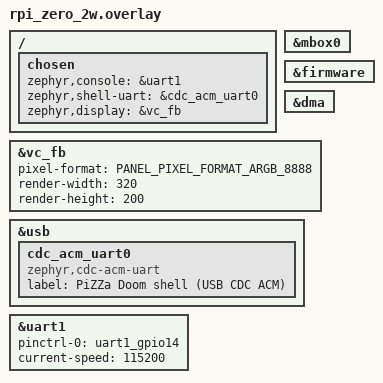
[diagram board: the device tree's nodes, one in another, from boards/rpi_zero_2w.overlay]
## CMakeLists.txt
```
# SPDX-License-Identifier: Apache-2.0
#
# PiZZa -- sdl2-doom via the shared minimal SDL2 shim (apps/lib/sdl2shim).
#
# Links the AlexOberhofer/sdl2-doom game sources (pure C, Chocolate-Doom
# lineage, UNTOUCHED at ~/github/sdl2-doom) against the shim. The one
# concession to "untouched" is a build-time rewrite of i_video.c's
# SDL_RESX/SDL_RESY from *3 to native 320x200: the fork bakes a 3x
# software upscale we do not want (the VC4 HVS scales instead). The
# checkout is not modified -- only a generated copy in the build tree.
#
# sdl2-doom is GPL-2.0; this binary is GPL-2.0 by virtue of linking it.
# The shim + port glue are Apache-2.0, same model as the SDLPoP port.

cmake_minimum_required(VERSION 3.20.0)

find_package(Zephyr REQUIRED HINTS $ENV{ZEPHYR_BASE})
project(pizza-doom C ASM)

# sample_usbd helper for the USB CDC ACM shell (rpi_zero_2w), same as
# PizzaShell / wipeout / SDLPoP.
if(CONFIG_USB_DEVICE_STACK_NEXT)
  include(${ZEPHYR_BASE}/samples/subsys/usb/common/common.cmake)
endif()

# ── Doom game tree (untouched) ──────────────────────────────────────
if(NOT DEFINED DOOM_SRC_DIR)
  set(DOOM_SRC_DIR "$ENV{HOME}/github/sdl2-doom/src")
endif()
if(NOT EXISTS "${DOOM_SRC_DIR}/d_main.c")
  message(FATAL_ERROR
    "sdl2-doom sources not found at ${DOOM_SRC_DIR}. Clone "
    "https://github.com/AlexOberhofer/sdl2-doom and keep it at "
    "~/github/sdl2-doom or pass -DDOOM_SRC_DIR=<path>.")
endif()

# The fork's own build list (its CMakeLists), minus i_cdmus.c (SDL 1.2
# CD API, absent in SDL2; grep confirms nothing else references
# I_CDMus*) and minus i_video.c, which is fed in rewritten below.
set(DOOM_GAME_SRC
  ${DOOM_SRC_DIR}/i_main.c ${DOOM_SRC_DIR}/dummy.c ${DOOM_SRC_DIR}/am_map.c
  ${DOOM_SRC_DIR}/doomdef.c ${DOOM_SRC_DIR}/doomstat.c ${DOOM_SRC_DIR}/dstrings.c
  ${DOOM_SRC_DIR}/d_event.c ${DOOM_SRC_DIR}/d_items.c ${DOOM_SRC_DIR}/d_iwad.c
  ${DOOM_SRC_DIR}/d_loop.c ${DOOM_SRC_DIR}/d_main.c ${DOOM_SRC_DIR}/d_mode.c
  ${DOOM_SRC_DIR}/d_net.c ${DOOM_SRC_DIR}/f_finale.c ${DOOM_SRC_DIR}/f_wipe.c
  ${DOOM_SRC_DIR}/g_game.c ${DOOM_SRC_DIR}/hu_lib.c ${DOOM_SRC_DIR}/hu_stuff.c
  ${DOOM_SRC_DIR}/info.c ${DOOM_SRC_DIR}/i_endoom.c ${DOOM_SRC_DIR}/i_joystick.c
  ${DOOM_SRC_DIR}/i_scale.c ${DOOM_SRC_DIR}/i_sound.c ${DOOM_SRC_DIR}/i_sdlmusic.c
  ${DOOM_SRC_DIR}/i_sdlsound.c ${DOOM_SRC_DIR}/i_system.c ${DOOM_SRC_DIR}/i_timer.c
  ${DOOM_SRC_DIR}/i_input.c ${DOOM_SRC_DIR}/mus2mid.c ${DOOM_SRC_DIR}/memio.c
  ${DOOM_SRC_DIR}/m_argv.c ${DOOM_SRC_DIR}/m_bbox.c ${DOOM_SRC_DIR}/m_cheat.c
  ${DOOM_SRC_DIR}/m_config.c ${DOOM_SRC_DIR}/m_controls.c ${DOOM_SRC_DIR}/m_fixed.c
  ${DOOM_SRC_DIR}/m_menu.c ${DOOM_SRC_DIR}/m_misc.c ${DOOM_SRC_DIR}/m_random.c
  ${DOOM_SRC_DIR}/p_ceilng.c ${DOOM_SRC_DIR}/p_doors.c ${DOOM_SRC_DIR}/p_enemy.c
  ${DOOM_SRC_DIR}/p_floor.c ${DOOM_SRC_DIR}/p_inter.c ${DOOM_SRC_DIR}/p_lights.c
  ${DOOM_SRC_DIR}/p_map.c ${DOOM_SRC_DIR}/p_maputl.c ${DOOM_SRC_DIR}/p_mobj.c
  ${DOOM_SRC_DIR}/p_plats.c ${DOOM_SRC_DIR}/p_pspr.c ${DOOM_SRC_DIR}/p_saveg.c
  ${DOOM_SRC_DIR}/p_setup.c ${DOOM_SRC_DIR}/p_sight.c ${DOOM_SRC_DIR}/p_spec.c
  ${DOOM_SRC_DIR}/p_switch.c ${DOOM_SRC_DIR}/p_telept.c ${DOOM_SRC_DIR}/p_tick.c
  ${DOOM_SRC_DIR}/p_user.c ${DOOM_SRC_DIR}/r_bsp.c ${DOOM_SRC_DIR}/r_data.c
  ${DOOM_SRC_DIR}/r_draw.c ${DOOM_SRC_DIR}/r_main.c ${DOOM_SRC_DIR}/r_plane.c
  ${DOOM_SRC_DIR}/r_segs.c ${DOOM_SRC_DIR}/r_sky.c ${DOOM_SRC_DIR}/r_things.c
  ${DOOM_SRC_DIR}/sha1.c ${DOOM_SRC_DIR}/sounds.c ${DOOM_SRC_DIR}/statdump.c
  ${DOOM_SRC_DIR}/st_lib.c ${DOOM_SRC_DIR}/st_stuff.c ${DOOM_SRC_DIR}/s_sound.c
  ${DOOM_SRC_DIR}/tables.c ${DOOM_SRC_DIR}/v_video.c ${DOOM_SRC_DIR}/wi_stuff.c
  ${DOOM_SRC_DIR}/w_checksum.c ${DOOM_SRC_DIR}/w_file.c ${DOOM_SRC_DIR}/w_main.c
  ${DOOM_SRC_DIR}/w_wad.c ${DOOM_SRC_DIR}/z_zone.c ${DOOM_SRC_DIR}/w_file_stdc.c
)

# i_video.c rewritten to native 320x200 (SDL_RESX/Y *3 -> plain). Keeps
# the checkout pristine; the whole delta is this two-line sed.
set(DOOM_IVIDEO_GEN ${CMAKE_BINARY_DIR}/gen/i_video_320.c)
add_custom_command(
  OUTPUT ${DOOM_IVIDEO_GEN}
  COMMAND ${CMAKE_COMMAND} -E make_directory ${CMAKE_BINARY_DIR}/gen
  COMMAND ${CMAKE_COMMAND} -E copy ${DOOM_SRC_DIR}/i_video.c ${DOOM_IVIDEO_GEN}
  COMMAND sed -i.bak
          -e "s|#define SDL_RESX 320 \\* 3|#define SDL_RESX 320|"
          -e "s|#define SDL_RESY 200 \\* 3|#define SDL_RESY 200|"
          ${DOOM_IVIDEO_GEN}
  DEPENDS ${DOOM_SRC_DIR}/i_video.c
  COMMENT "Rewriting i_video.c to native 320x200 (HVS upscales)"
  VERBATIM
)
list(APPEND DOOM_GAME_SRC ${DOOM_IVIDEO_GEN})

# OPL music: the fork's InitMusicModule hardcodes music_sdl_module. Swap it
# to music_opl_module (from the ported i_oplmusic.c) via a build-dir gen
# copy -- pristine checkout, same as the i_video rewrite.
if(CONFIG_DOOM_MUSIC_OPL)
  list(REMOVE_ITEM DOOM_GAME_SRC ${DOOM_SRC_DIR}/i_sound.c)
  set(DOOM_ISOUND_GEN ${CMAKE_BINARY_DIR}/gen/i_sound_opl.c)
  add_custom_command(
    OUTPUT ${DOOM_ISOUND_GEN}
    COMMAND ${CMAKE_COMMAND} -E make_directory ${CMAKE_BINARY_DIR}/gen
    COMMAND ${CMAKE_COMMAND} -E copy ${DOOM_SRC_DIR}/i_sound.c ${DOOM_ISOUND_GEN}
    COMMAND sed -i.bak
            -e "s|music_module = &music_sdl_module|music_module = \\&music_opl_module|"
            ${DOOM_ISOUND_GEN}
    DEPENDS ${DOOM_SRC_DIR}/i_sound.c
    COMMENT "Selecting OPL music module (music_sdl -> music_opl)"
    VERBATIM
  )
  list(APPEND DOOM_GAME_SRC ${DOOM_ISOUND_GEN})
endif()

# ── shim ────────────────────────────────────────────────────────────
include(${CMAKE_CURRENT_SOURCE_DIR}/../lib/sdl2shim/sdl2shim.cmake)

set(DOOM_SHIM_SRC
  src/shim_main.c
  src/shim_video.c
  src/shim_mixer.c
  src/doom_assets.c
  src/doom_pack.S
)

if(CONFIG_DOOM_PRESENT_DISPLAY)
  list(APPEND DOOM_SHIM_SRC src/doom_present_display.c)
elseif(CONFIG_DOOM_PRESENT_SEMIHOST)
  list(APPEND DOOM_SHIM_SRC src/doom_present_semihost.c)
else()
  list(APPEND DOOM_SHIM_SRC src/doom_present_none.c)
endif()

# Audio backend (lib-owned choice): qemu uses "none" (Mix_OpenAudio
# fails, Doom silent); rpi_zero_2w uses the HDMI/MAI backend the mixer
# feeds through s2s_audio_open.
if(CONFIG_SDL2SHIM_AUDIO_HDMI)
  list(APPEND DOOM_SHIM_SRC ${SDL2SHIM_AUDIO_HDMI_SOURCES})
else()
  list(APPEND DOOM_SHIM_SRC ${SDL2SHIM_AUDIO_NONE})
endif()

# OPL music (CONFIG_DOOM_MUSIC_OPL): Chocolate Doom's OPL synth, referenced
# from the Chocolate checkout (like the game tree is from sdl2-doom). Nuked
# OPL3 emulator + i_oplmusic sequencer + opl_sdl driver (folds into the
# mixer as a MIX_CHANNEL_POST effect); opl_glue.c supplies the SDL
# mutex/cond + SDL_MixAudioFormat the OPL code expects. Flags + includes are
# applied below alongside the game TUs.
if(CONFIG_DOOM_MUSIC_OPL)
  if(NOT DEFINED CHOCOLATE_SRC_DIR)
    set(CHOCOLATE_SRC_DIR "$ENV{HOME}/github/chocolate-doom")
  endif()
  if(NOT EXISTS "${CHOCOLATE_SRC_DIR}/opl/opl3.c")
    message(FATAL_ERROR
      "OPL music needs chocolate-doom at ${CHOCOLATE_SRC_DIR} "
      "(opl/ + src/i_oplmusic.c). Pass -DCHOCOLATE_SRC_DIR=<path>.")
  endif()
  # i_oplmusic.c is referenced pristine: it sits next to Chocolate's own
  # headers, so its ""-includes resolve to Chocolate's (self-consistent),
  # and its music_module_t is layout-compatible with the fork's.
  set(DOOM_OPL_SRC
    ${CHOCOLATE_SRC_DIR}/opl/opl.c
    ${CHOCOLATE_SRC_DIR}/opl/opl3.c
    ${CHOCOLATE_SRC_DIR}/opl/opl_queue.c
    ${CHOCOLATE_SRC_DIR}/opl/opl_sdl.c
    ${CHOCOLATE_SRC_DIR}/src/midifile.c
    ${CHOCOLATE_SRC_DIR}/src/i_oplmusic.c
  )
  list(APPEND DOOM_SHIM_SRC ${DOOM_OPL_SRC} src/opl_glue.c)
endif()

# USB device bring-up + the `doom` shell = interactive input on hardware.
if(CONFIG_USB_DEVICE_STACK_NEXT)
  list(APPEND DOOM_SHIM_SRC ${SDL2SHIM_USB})
endif()
if(CONFIG_SHELL)
  list(APPEND DOOM_SHIM_SRC src/doom_shell.c)
endif()

if(CONFIG_DOOM_SCRIPTED_INPUT)
  # Doom brings its own timeline; the lib's shim_scripted has SDLPoP's.
  list(APPEND DOOM_SHIM_SRC src/doom_scripted.c)
endif()

# ── IWAD bake (§5): raw .incbin into rodata ─────────────────────────
if(NOT DEFINED DOOM_WAD)
  # Prefer a complete shareware/retail IWAD; fall back to the minimal
  # test IWAD (boots + inits, but lacks title/music/map lumps).
  if(EXISTS "$ENV{HOME}/github/doom1.wad")
    set(DOOM_WAD "$ENV{HOME}/github/doom1.wad")
  else()
    set(DOOM_WAD "$ENV{HOME}/github/chocolate-doom/quickcheck/iwads/miniwad.wad")
  endif()
endif()
if(NOT EXISTS "${DOOM_WAD}")
  message(FATAL_ERROR "IWAD not found: ${DOOM_WAD}. Pass -DDOOM_WAD=<path/to/doom1.wad>.")
endif()
set(DOOM_WAD_BIN ${CMAKE_BINARY_DIR}/doom_iwad.wad)
add_custom_command(
  OUTPUT ${DOOM_WAD_BIN}
  COMMAND ${CMAKE_COMMAND} -E copy ${DOOM_WAD} ${DOOM_WAD_BIN}
  DEPENDS ${DOOM_WAD}
  COMMENT "Baking IWAD ${DOOM_WAD} into rodata"
)
add_custom_target(doom_wad_bake DEPENDS ${DOOM_WAD_BIN})
add_dependencies(app doom_wad_bake)
set_source_files_properties(src/doom_pack.S PROPERTIES
  OBJECT_DEPENDS ${DOOM_WAD_BIN}
  COMPILE_OPTIONS "-I${CMAKE_BINARY_DIR};-Wa,-I${CMAKE_BINARY_DIR}"
)

# ── target ──────────────────────────────────────────────────────────
target_sources(app PRIVATE
  ${DOOM_GAME_SRC}
  ${DOOM_SHIM_SRC}
  ${SDL2SHIM_CORE_SOURCES}
)

# include/ order: shim SDL2 headers first so <SDL2/SDL.h> and
# <SDL2/SDL_mixer.h> resolve to the shim, then the game headers.
target_include_directories(app PRIVATE
  ${SDL2SHIM_INCLUDE_DIRS}
  ${CMAKE_CURRENT_SOURCE_DIR}/src
  ${DOOM_SRC_DIR}/../include
  ${DOOM_SRC_DIR}
)

# Game TUs assume glibc (strcasecmp/alloca via string.h/stdlib.h);
# picolibc keeps them in <strings.h>/<alloca.h>. Silence the pedantic
# warnings the upstream build silences too.
#
# FEATURE_SOUND: sdl2-doom gates its SFX module table (i_sound.c
# sound_modules[]) behind this, and defines it from the makefile
# (CFLAGS+=-DFEATURE_SOUND), NOT config.h. Without it InitSfxModule finds
# no module -> sound_module stays NULL -> I_StartSound never dispatches ->
# silent SFX (music still plays: InitMusicModule hardcodes its module past
# the ifdef, which is what masked this as "mixer open, 0 mix calls").
set_source_files_properties(${DOOM_GAME_SRC} PROPERTIES COMPILE_OPTIONS
  "-Wno-unused-variable;-Wno-unused-but-set-variable;-Wno-missing-braces;-Wno-unused-function;-Wno-maybe-uninitialized;-Wno-implicit-fallthrough;-Wno-format;-Wno-int-conversion;-include;strings.h;-include;alloca.h;-D_DEFAULT_SOURCE;-DFEATURE_SOUND"
)

# i_main.c defines main(argc,argv) but does not include <SDL2/SDL.h>, so
# the header's main->SDL_main redirect can't reach it; force it here so
# shim_main.c's main(void) is the Zephyr entry.
set_source_files_properties(${DOOM_SRC_DIR}/i_main.c PROPERTIES
  COMPILE_DEFINITIONS "main=SDL_main")

# OPL TUs (from the Chocolate checkout). i_oplmusic.c + midifile.c sit next
# to Chocolate's own headers, so their ""-includes (i_sound.h etc.) resolve
# to Chocolate's -- self-consistent, and its music_module_t is layout-
# compatible with the fork's (only a const qualifier differs), so
# music_opl_module links against the fork's InitMusicModule. Add opl/ + src/
# for the OPL-only headers, and the shim's SDL2/ dir for the bare "SDL.h".
if(CONFIG_DOOM_MUSIC_OPL)
  target_include_directories(app PRIVATE
    ${CHOCOLATE_SRC_DIR}/opl
    ${CHOCOLATE_SRC_DIR}/src
    ${CMAKE_CURRENT_SOURCE_DIR}/../lib/sdl2shim/include/SDL2
  )
  set(OPL_FLAGS "-Wno-unused-variable;-Wno-unused-but-set-variable;-Wno-unused-function;-Wno-missing-braces;-Wno-implicit-fallthrough;-Wno-format;-Wno-maybe-uninitialized;-Wno-int-conversion;-include;strings.h;-D_DEFAULT_SOURCE")
  set_source_files_properties(${DOOM_OPL_SRC} PROPERTIES COMPILE_OPTIONS "${OPL_FLAGS}")
endif()
```

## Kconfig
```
# SPDX-License-Identifier: Apache-2.0
#
# PiZZa sdl2-doom port -- app options. Backend choices are the seams the
# app's CMakeLists uses to pick the present/audio TU.

# SAMPLE_USBD_* options for sample_usbd_init.c on boards with the USB
# device stack (rpi_zero_2w).
source "samples/subsys/usb/common/Kconfig.sample_usbd"

rsource "../lib/sdl2shim/Kconfig"

menu "PiZZa sdl2-doom port"

choice DOOM_PRESENT_BACKEND
	prompt "Frame present backend"
	default DOOM_PRESENT_DISPLAY if DISPLAY
	default DOOM_PRESENT_NONE

config DOOM_PRESENT_DISPLAY
	bool "Zephyr display API (bcm2835_fb + HVS scaling on hardware)"
	depends on DISPLAY

config DOOM_PRESENT_NONE
	bool "Drop frames (link/sim bring-up)"

config DOOM_PRESENT_SEMIHOST
	bool "Semihosting PPM capture (qemu sim gates)"
	depends on SEMIHOST

endchoice

config DOOM_CAPTURE_EVERY
	int "Capture every Nth presented frame (0 = first frame only)"
	depends on DOOM_PRESENT_SEMIHOST
	default 0

config DOOM_SCRIPTED_INPUT
	bool "Drive Doom from a scripted synthetic input source"
	default n

config DOOM_SIM_TUNING
	bool "Boot straight to E1M1 (-warp 1 1) for qemu sim gates"
	default n
	help
	  The title/demo loop renders far too slowly under qemu TCG to
	  reach interactively; -warp 1 1 drops straight into E1M1 so the
	  sim gates can capture gameplay. Requires an IWAD that contains
	  E1M1 (the shareware doom1.wad; the miniwad does not).

config DOOM_MUSIC_OPL
	bool "OPL2/OPL3 FM music (Chocolate Doom synth via GENMIDI)"
	default n
	help
	  Real Doom music: compiles Chocolate Doom's OPL subsystem (Nuked
	  OPL3 emulator + i_oplmusic sequencer, referenced from
	  CHOCOLATE_SRC_DIR) and folds the synth into the mixer via a
	  MIX_CHANNEL_POST effect. Instruments come from the WAD's GENMIDI
	  lump -- no external data. Replaces the silent music stubs.

endmenu

source "Kconfig.zephyr"
```

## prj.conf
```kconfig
# SPDX-License-Identifier: Apache-2.0
#
# Common config for the PiZZa sdl2-doom port. Per-board overrides
# (display, USB, audio) live in boards/<board>.conf.

CONFIG_PRINTK=y
CONFIG_BOOT_BANNER=y
CONFIG_LOG_PRINTK=n

# picolibc errno needs TLS -- same hard-won stanza as the wipeout and
# SDLPoP ports; without it the first failing stdio call scribbles
# through a wild TPIDRRO_EL0 offset.
CONFIG_TOOLCHAIN_CROSS_COMPILE_SUPPORTS_THREAD_LOCAL_STORAGE=y
CONFIG_THREAD_LOCAL_STORAGE=y

# Doom mallocs its zone heap (Z_Init), the 320x200 texture/backbuffers
# and sound-chunk cache. 24 MiB covers the classic zone plus headroom
# on both the 512 MiB board and qemu.
CONFIG_COMMON_LIBC_MALLOC_ARENA_SIZE=25165824

# The game runs on the Zephyr main thread; the renderer and menu call
# chains run deep.
CONFIG_MAIN_STACK_SIZE=65536

CONFIG_FPU=y
CONFIG_STACK_SENTINEL=y
CONFIG_ASSERT=y
```

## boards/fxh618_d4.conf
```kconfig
# SPDX-License-Identifier: Apache-2.0
#
# FX-H618-D4 TV box (Allwinner H618, Cortex-A53 x4, AArch64) -- sdl2-doom.
# HDMI through the DE33 -> TCON-TV0 -> DW-HDMI pipeline at a fixed
# 1080p60, with the driver's render surface set to Doom's native 320x200
# in the board overlay and scaled up in hardware terms by the driver.
# Console, logs and the `doom` shell all share uart0.
#
# No audio: this box has no analog output and the DW-HDMI audio path is
# not driven yet, so the shim falls back to its "none" backend and Doom
# runs silent. HDMI audio is a separate work order.

# HDMI display via the sunxi DE33 pipeline, ARGB_8888.
CONFIG_DISPLAY=y
CONFIG_DISPLAY_SUNXI_DE33=y

# Shell on the board console. The bench snippet already supplies
# CONFIG_SHELL/KERNEL_SHELL/PSCI_SHELL; these are the Doom-side extras.
CONFIG_SHELL=y
CONFIG_SHELL_BACKEND_SERIAL=y
CONFIG_SHELL_STACK_SIZE=8192
CONFIG_SHELL_VT100_COMMANDS=y
CONFIG_SHELL_HISTORY=y
CONFIG_SHELL_TAB=y
CONFIG_SHELL_LOG_BACKEND=n

# Logging on the same UART, kept off the shell prompt.
CONFIG_LOG=y
CONFIG_LOG_BUFFER_SIZE=16384
CONFIG_LOG_BACKEND_UART=y
CONFIG_LOG_MODE_DEFERRED=y
CONFIG_DEVMEM_SHELL=y
```

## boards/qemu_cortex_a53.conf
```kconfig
# SPDX-License-Identifier: Apache-2.0
#
# qemu_cortex_a53 -- SIM target for the work-order's sim-verified gates.
# No display hardware: frames leave the guest as PPM files via
# semihosting (doom_present_semihost.c). qemu gets the semihosting flags
# from cmake/emu/qemu.cmake when CONFIG_SEMIHOST.

# Run the emulated CPU at wall speed; -icount stretches this
# software-rendered workload badly. Doom's own timing keeps pace.
CONFIG_QEMU_ICOUNT=n

CONFIG_SEMIHOST=y
CONFIG_DOOM_PRESENT_SEMIHOST=y
CONFIG_DOOM_CAPTURE_EVERY=35

# G2: scripted input drives the menu -> New Game -> E1M1 -> move/fire.
CONFIG_DOOM_SCRIPTED_INPUT=y

# SIM_TUNING (-warp 1 1) needs an IWAD with E1M1; enable once doom1.wad
# is baked (miniwad has no maps).
# CONFIG_DOOM_SIM_TUNING=y

CONFIG_LOG=y
CONFIG_LOG_MODE_MINIMAL=y
CONFIG_SDL2SHIM_LOG_LEVEL_DBG=y
```

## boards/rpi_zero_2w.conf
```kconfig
# SPDX-License-Identifier: Apache-2.0
#
# Raspberry Pi Zero 2 W (BCM2710, Cortex-A53, AArch64) -- sdl2-doom.
# Single-core (Doom is single-threaded DOS logic; no SMP). Console +
# logs on the mini-UART, interactive `doom` shell on USB CDC ACM, HDMI
# via the VC firmware framebuffer with HVS 320x200 scaling, SFX over MAI.

CONFIG_BOOT_DELAY=200

# VC mailbox + firmware (framebuffer alloc chain).
CONFIG_RASPBERRYPI_FIRMWARE=y

# HDMI display via VC firmware FB, ARGB_8888. The shim paints Doom's
# native 320x200 frame into the virtual FB; HVS scales to the monitor.
CONFIG_DISPLAY=y
CONFIG_BCM2835_FB=y

# BCM2835 DMA -- FB driver claims a channel for the backbuffer blit;
# the HDMI audio backend claims a second (cyclic, DREQ 17 -> MAI).
CONFIG_DMA=y
CONFIG_DMA_BCM2835=y

# HDMI audio via VC4 MAI: the mixer's 44.1 kHz output is resampled to
# 48 kHz, IEC958-packed and DMA-fed into the MAI FIFO on the HDMI output
# the firmware already drives. 8-block ring needs 8 control blocks.
# Requires hdmi_drive=2 in config.txt and a display that accepts audio.
CONFIG_SDL2SHIM_AUDIO_HDMI=y
CONFIG_DMA_BCM2835_MAX_CBS_PER_CHANNEL=8

# USB CDC ACM shell, same shape as PizzaShell/wipeout. The `doom`
# command set (inject keys, audio diagnostics) registers here.
CONFIG_USB_DEVICE_STACK_NEXT=y
CONFIG_UDC_DWC2=y
CONFIG_UDC_DWC2_DMA=n
CONFIG_SERIAL=y
CONFIG_USBD_CDC_ACM_CLASS=y
CONFIG_CDC_ACM_SERIAL_INITIALIZE_AT_BOOT=n
CONFIG_SAMPLE_USBD_PRODUCT="PiZZa Doom -- rpi_zero_2w"
CONFIG_SAMPLE_USBD_MANUFACTURER="jetpax/PiZZa"
CONFIG_SAMPLE_USBD_PID=0xCAFE
CONFIG_USBD_THREAD_STACK_SIZE=4096
CONFIG_UDC_DWC2_STACK_SIZE=4096

CONFIG_SHELL=y
CONFIG_SHELL_BACKEND_SERIAL=y
CONFIG_KERNEL_SHELL=y
CONFIG_SHELL_STACK_SIZE=8192
CONFIG_SHELL_VT100_COMMANDS=y
CONFIG_SHELL_HISTORY=y
CONFIG_SHELL_TAB=y
CONFIG_SHELL_LOG_BACKEND=n

# Logging on the board console (mini-UART), off the shell prompt.
CONFIG_LOG=y
CONFIG_LOG_BUFFER_SIZE=16384
CONFIG_LOG_BACKEND_UART=y
CONFIG_LOG_MODE_DEFERRED=y
CONFIG_USBD_CDC_ACM_LOG_LEVEL_WRN=y
CONFIG_USBD_LOG_LEVEL_INF=y
CONFIG_UDC_DRIVER_LOG_LEVEL_WRN=y
```

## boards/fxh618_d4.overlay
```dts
/*
 * SPDX-License-Identifier: Apache-2.0
 *
 * PiZZa sdl2-doom overlay for fxh618_d4 (Allwinner H618 TV box).
 *
 * The board already enables the DE33 -> TCON-TV0 -> DW-HDMI pipeline and
 * points zephyr,display at it, so all this has to do is ask for a render
 * surface at Doom's native size. The display driver reports 320x200
 * capabilities and scales x5 to 1600x1000 centred in the 1080p60 mode,
 * which is the same division of labour as the VideoCore HVS on
 * rpi_zero_2w -- the port itself is board-agnostic.
 *
 * Console, shell and logs all share uart0 (the board's only header UART,
 * 115200 8N1): no USB CDC endpoint on this box, so the `doom` shell
 * command set shares the port with the log output.
 */

&display {
	render-width = <320>;
	render-height = <200>;
};
```

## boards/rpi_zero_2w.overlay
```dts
/*
 * SPDX-License-Identifier: Apache-2.0
 *
 * PiZZa sdl2-doom overlay for rpi_zero_2w.
 *
 *   - &mbox0 + &firmware: VC mailbox + property tags (FB alloc).
 *   - &vc_fb: HDMI framebuffer at the monitor's EDID-negotiated scanout
 *     mode; the shim paints Doom's native 320x200 frame into the virtual
 *     FB and the VideoCore HVS scales it to the cable on the fly -- the
 *     same proven trick as the Jet / wipeout / SDLPoP ports. 320 * 4 =
 *     1280 bytes/row = 64-byte aligned, so the FB driver's
 *     contiguous-DMA fast path engages.
 *   - &dma: BCM2835 DMA (backbuffer->fb blit + the MAI audio feed).
 *   - &usb + cdc_acm child: USB CDC ACM `doom` shell endpoint.
 *   - mini-UART (uart1) console + LOG target, PiZZa convention.
 */

#include <zephyr/dt-bindings/display/panel.h>

&mbox0 {
	status = "okay";
};

&firmware {
	status = "okay";
};

&dma {
	status = "okay";
};

&vc_fb {
	pixel-format = <PANEL_PIXEL_FORMAT_ARGB_8888>;
	render-width = <320>;
	render-height = <200>;
	status = "okay";
};

&usb {
	status = "okay";

	cdc_acm_uart0: cdc_acm_uart0 {
		compatible = "zephyr,cdc-acm-uart";
		label = "PiZZa Doom shell (USB CDC ACM)";
	};
};

/ {
	chosen {
		zephyr,console = &uart1;
		zephyr,shell-uart = &cdc_acm_uart0;
		zephyr,display = &vc_fb;
	};
};

&uart1 {
	pinctrl-names = "default";
	pinctrl-0 = <&uart1_gpio14>;
	status = "okay";
	current-speed = <115200>;
};
```

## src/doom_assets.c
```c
/*
 * SPDX-License-Identifier: Apache-2.0
 *
 * PiZZa sdl2-doom -- embedded IWAD store (work-order §5).
 *
 * The shareware WAD is linked into .rodata (doom_pack.S, .incbin); this
 * file serves it through a POSIX fd layer, so w_file_stdc.c's fopen/fread/
 * fseek (funnelled by picolibc tinystdio through open/read/lseek/close/
 * fstat) resolve here with no filesystem on the boot path and the Doom
 * tree untouched.
 *
 * Two backing files: the read-only IWAD (any "*.wad" path), and -- when
 * OPL music is built -- ONE writable RAM temp file, "doom.mid". The OPL
 * music path round-trips each converted song through M_TempFile("doom.mid")
 * -> M_WriteFile -> MIDI_LoadFile; the fork's M_WriteFile and Chocolate's
 * MIDI_LoadFile both funnel through open()/read()/write(), so backing that
 * one path with RAM here makes the write and read see the same bytes.
 * Everything else is ENOENT; other writes fail EROFS.
 */

#include <zephyr/kernel.h>
#include <errno.h>
#include <fcntl.h>
#include <stdint.h>
#include <string.h>
#include <strings.h>
#include <sys/stat.h>
#include <sys/types.h>
#include <unistd.h>

extern const uint8_t doom_wad_start[];
extern const uint8_t doom_wad_end[];

#define DOOM_FD_BASE 3
#define DOOM_FD_MAX  4

enum fd_kind {
	FD_FREE = 0,
	FD_WAD,
	FD_TEMP,
};

static struct {
	size_t pos;
	enum fd_kind kind;
} fds[DOOM_FD_MAX];

/* Writable RAM temp file (the OPL MUS->MIDI round-trip). A Doom MIDI is a
 * few KB; 96 KiB matches i_oplmusic's MAXMIDLENGTH ceiling.
 */
#define MID_MAX (96 * 1024)
static uint8_t mid_buf[MID_MAX];
static size_t mid_len;

static size_t wad_size(void)
{
	return (size_t)(doom_wad_end - doom_wad_start);
}

static bool is_wad(const char *path)
{
	if (path == NULL) {
		return false;
	}

	size_t n = strlen(path);

	return n >= 4 && strcasecmp(path + n - 4, ".wad") == 0;
}

static bool is_temp(const char *path)
{
	if (path == NULL) {
		return false;
	}

	size_t n = strlen(path);

	return n >= 8 && strcasecmp(path + n - 8, "doom.mid") == 0;
}

int open(const char *path, int flags, ...)
{
	bool wr = (flags & O_ACCMODE) != O_RDONLY;
	enum fd_kind kind;

	if (is_temp(path)) {
		kind = FD_TEMP;
		if (wr) {
			mid_len = 0; /* truncate on write-open */
		}
	} else if (wr) {
		errno = EROFS;
		return -1;
	} else if (!is_wad(path) || wad_size() == 0) {
		errno = ENOENT;
		return -1;
	} else {
		kind = FD_WAD;
	}

	for (int i = 0; i < DOOM_FD_MAX; i++) {
		if (fds[i].kind == FD_FREE) {
			fds[i].pos = 0;
			fds[i].kind = kind;
			return DOOM_FD_BASE + i;
		}
	}
	errno = EMFILE;
	return -1;
}

static int fd_slot(int fd)
{
	int i = fd - DOOM_FD_BASE;

	if (i < 0 || i >= DOOM_FD_MAX || fds[i].kind == FD_FREE) {
		return -1;
	}
	return i;
}

static size_t fd_size(int i)
{
	return (fds[i].kind == FD_TEMP) ? mid_len : wad_size();
}

int close(int fd)
{
	int i = fd_slot(fd);

	if (i < 0) {
		errno = EBADF;
		return -1;
	}
	fds[i].kind = FD_FREE;
	return 0;
}

ssize_t read(int fd, void *buf, size_t count)
{
	int i = fd_slot(fd);

	if (i < 0) {
		errno = EBADF;
		return -1;
	}

	const uint8_t *src = (fds[i].kind == FD_TEMP) ? mid_buf : doom_wad_start;
	size_t avail = fd_size(i) - fds[i].pos;
	size_t n = MIN(count, avail);

	memcpy(buf, src + fds[i].pos, n);
	fds[i].pos += n;
	return (ssize_t)n;
}

ssize_t write(int fd, const void *buf, size_t count)
{
	int i = fd_slot(fd);

	if (i < 0) {
		errno = EBADF;
		return -1;
	}
	if (fds[i].kind != FD_TEMP) {
		errno = EROFS;
		return -1;
	}

	size_t space = MID_MAX - fds[i].pos;
	size_t n = MIN(count, space);

	memcpy(mid_buf + fds[i].pos, buf, n);
	fds[i].pos += n;
	if (fds[i].pos > mid_len) {
		mid_len = fds[i].pos;
	}
	if (n < count) {
		errno = ENOSPC;
	}
	return (ssize_t)n;
}

off_t lseek(int fd, off_t offset, int whence)
{
	int i = fd_slot(fd);

	if (i < 0) {
		errno = EBADF;
		return (off_t)-1;
	}

	off_t fsize = (off_t)fd_size(i);
	off_t base;

	switch (whence) {
	case SEEK_SET:
		base = 0;
		break;
	case SEEK_CUR:
		base = (off_t)fds[i].pos;
		break;
	case SEEK_END:
		base = fsize;
		break;
	default:
		errno = EINVAL;
		return (off_t)-1;
	}

	off_t target = base + offset;

	if (target < 0 || target > fsize) {
		errno = EINVAL;
		return (off_t)-1;
	}
	fds[i].pos = (size_t)target;
	return target;
}

int fstat(int fd, struct stat *st)
{
	int i = fd_slot(fd);

	if (i < 0) {
		errno = EBADF;
		return -1;
	}
	memset(st, 0, sizeof(*st));
	st->st_size = (off_t)fd_size(i);
	st->st_mode = S_IFREG | ((fds[i].kind == FD_TEMP) ? 0644 : 0444);
	return 0;
}

int stat(const char *path, struct stat *st)
{
	bool temp = is_temp(path);

	if (!temp && (!is_wad(path) || wad_size() == 0)) {
		errno = ENOENT;
		return -1;
	}
	memset(st, 0, sizeof(*st));
	st->st_size = temp ? (off_t)mid_len : (off_t)wad_size();
	st->st_mode = S_IFREG | (temp ? 0644 : 0444);
	return 0;
}

int access(const char *path, int mode)
{
	if (is_temp(path)) {
		return 0;
	}
	if (!is_wad(path) || wad_size() == 0) {
		errno = ENOENT;
		return -1;
	}
	if ((mode & W_OK) != 0) {
		errno = EROFS;
		return -1;
	}
	return 0;
}

int remove(const char *path)
{
	if (is_temp(path)) {
		mid_len = 0;
		return 0;
	}
	errno = EROFS;
	return -1;
}
```

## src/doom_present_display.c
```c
/*
 * SPDX-License-Identifier: Apache-2.0
 *
 * PiZZa sdl2-doom -- display present backend (CONFIG_DOOM_PRESENT_DISPLAY).
 *
 * Pushes Doom's 320x200 XRGB8888 frame at the Zephyr display API and
 * lets the display driver own the scaling, so this backend is
 * board-agnostic. On rpi_zero_2w that driver is bcm2835_fb with a
 * 320x200 virtual framebuffer (320 * 4 = 1280 B/row, 64-byte aligned so
 * its contiguous-DMA fast path engages) and the VideoCore HVS scales to
 * the monitor's native mode; on fxh618_d4 it is the sunxi DE33 pipeline
 * with a 320x200 render surface scaled x5 into a fixed 1080p60 mode.
 * Either way the contract is the same: capabilities report the render
 * size, and a full frame goes out per present.
 *
 * Doom's pixels are already 0x00RRGGBB; the scanout wants 0xFFRRGGBB,
 * so the only conversion is forcing the alpha/x byte opaque.
 */

#include <zephyr/kernel.h>
#include <zephyr/device.h>
#include <zephyr/drivers/display.h>
#include <zephyr/logging/log.h>

#include "sdl2shim.h"

LOG_MODULE_REGISTER(doom_present, CONFIG_SDL2SHIM_LOG_LEVEL);

#define DOOM_W 320
#define DOOM_H 200

static const struct device *display_dev;
static uint32_t backbuf[DOOM_W * DOOM_H];
static bool ready;

int s2s_present_init(int width, int height)
{
	if (width != DOOM_W || height != DOOM_H) {
		LOG_ERR("present: %dx%d requested, backend is fixed %dx%d",
			width, height, DOOM_W, DOOM_H);
		return -EINVAL;
	}

	display_dev = DEVICE_DT_GET(DT_CHOSEN(zephyr_display));
	if (!device_is_ready(display_dev)) {
		LOG_ERR("present: display device not ready -- HDMI not connected?");
		return -ENODEV;
	}

	struct display_capabilities caps;

	display_get_capabilities(display_dev, &caps);
	LOG_INF("present: display %ux%u (render surface) fmt=0x%x",
		caps.x_resolution, caps.y_resolution,
		(unsigned int)caps.current_pixel_format);

	if (caps.x_resolution != DOOM_W || caps.y_resolution != DOOM_H) {
		LOG_WRN("present: display reports %ux%u, expected %ux%u "
			"(check render-width/render-height in overlay)",
			caps.x_resolution, caps.y_resolution, DOOM_W, DOOM_H);
	}

	ready = true;
	return 0;
}

void s2s_present_frame(const void *xrgb_pixels, int pitch)
{
	if (!ready) {
		return;
	}

	const uint8_t *src_row = xrgb_pixels;
	uint32_t *dst = backbuf;

	for (int y = 0; y < DOOM_H; y++) {
		const uint32_t *px = (const uint32_t *)src_row;

		for (int x = 0; x < DOOM_W; x++) {
			*dst++ = 0xFF000000u | (px[x] & 0x00FFFFFFu);
		}
		src_row += pitch;
	}

	struct display_buffer_descriptor desc = {
		.buf_size = sizeof(backbuf),
		.width = DOOM_W,
		.height = DOOM_H,
		.pitch = DOOM_W,
		.frame_incomplete = false,
	};

	uint32_t t0 = k_cycle_get_32();
	int rc = display_write(display_dev, 0, 0, &desc, backbuf);
	uint32_t dt = k_cycle_get_32() - t0;

	if (rc != 0) {
		LOG_ERR("present: display_write rc=%d", rc);
	}

	/* Frame rate over the last 200 presents, and how much of the frame
	 * went into the display driver. The split matters: a driver that
	 * scales in software (fxh618_d4) charges a fixed cost per frame
	 * here, one that scales in hardware (rpi_zero_2w HVS) charges
	 * almost nothing, and the difference decides whether a frame-rate
	 * problem is the game or the scanout path.
	 */
	static uint32_t frames;
	static uint64_t write_cycles;
	static int64_t window_start;

	write_cycles += dt;
	if (++frames == 200U) {
		int64_t now = k_uptime_get();
		int64_t ms = now - window_start;
		uint32_t write_us = (uint32_t)(write_cycles /
			(sys_clock_hw_cycles_per_sec() / 1000000U) / frames);

		if (window_start != 0 && ms > 0) {
			LOG_INF("present: %u frames in %lld ms (%lld.%02lld fps), "
				"display_write %u us of %lld us per frame",
				frames, ms, 200000 / ms,
				(200000 * 100 / ms) % 100, write_us,
				ms * 1000 / frames);
		}
		window_start = now;
		frames = 0U;
		write_cycles = 0U;
	}
}
```

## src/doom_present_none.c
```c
/*
 * SPDX-License-Identifier: Apache-2.0
 *
 * PiZZa sdl2-doom -- "none" present backend (CONFIG_DOOM_PRESENT_NONE).
 * Frames are dropped; a periodic counter on the log confirms the game
 * is presenting. Link/sim bring-up before the capture or display
 * backend is wired.
 */

#include <zephyr/kernel.h>
#include <zephyr/logging/log.h>

#include "sdl2shim.h"

LOG_MODULE_REGISTER(doom_present, CONFIG_SDL2SHIM_LOG_LEVEL);

static uint32_t frames;

int s2s_present_init(int width, int height)
{
	LOG_INF("present: none backend (%dx%d frames dropped)", width, height);
	return 0;
}

void s2s_present_frame(const void *xrgb_pixels, int pitch)
{
	ARG_UNUSED(xrgb_pixels);
	ARG_UNUSED(pitch);

	frames++;
	if ((frames % 64) == 0) {
		LOG_INF("present: %u frames", frames);
	}
}
```

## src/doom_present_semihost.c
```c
/*
 * SPDX-License-Identifier: Apache-2.0
 *
 * PiZZa sdl2-doom -- semihosting capture present backend
 * (CONFIG_DOOM_PRESENT_SEMIHOST, qemu sim gates).
 *
 * Frames land on the host filesystem as binary PPM (P6) files. Doom's
 * texture is 320x200 XRGB8888 (0x00RRGGBB per pixel); PPM wants R,G,B
 * bytes, so each pixel is unpacked on the way out.
 *
 * Frame 1 is always written; with CONFIG_DOOM_CAPTURE_EVERY=N > 0 every
 * Nth frame is written too.
 */

#include <zephyr/kernel.h>
#include <zephyr/arch/common/semihost.h>
#include <zephyr/logging/log.h>
#include <stdio.h>

#include "sdl2shim.h"

LOG_MODULE_REGISTER(doom_present, CONFIG_SDL2SHIM_LOG_LEVEL);

static int fb_w;
static int fb_h;
static uint32_t frames;

int s2s_present_init(int width, int height)
{
	fb_w = width;
	fb_h = height;
	LOG_INF("present: semihost capture backend (%dx%d)", width, height);
	return 0;
}

void s2s_present_frame(const void *xrgb_pixels, int pitch)
{
	frames++;

	bool capture = (frames == 1);

	if (CONFIG_DOOM_CAPTURE_EVERY > 0 &&
	    (frames % CONFIG_DOOM_CAPTURE_EVERY) == 0) {
		capture = true;
	}
	if (!capture) {
		return;
	}

	char name[48];
	char header[32];

	snprintf(name, sizeof(name), "doom_frame_%06u.ppm", frames);

	long fd = semihost_open(name, SEMIHOST_OPEN_WB);

	if (fd < 0) {
		LOG_ERR("present: semihost_open(%s) = %ld", name, fd);
		return;
	}

	int hlen = snprintf(header, sizeof(header), "P6\n%d %d\n255\n", fb_w, fb_h);

	semihost_write(fd, header, hlen);

	/* Unpack XRGB -> RGB one row at a time: 200 semihost writes/frame,
	 * not 64000. Row buffer sized for the wired 320-wide frame.
	 */
	static uint8_t rowbuf[320 * 3];
	const uint8_t *row = xrgb_pixels;

	for (int y = 0; y < fb_h; y++) {
		const uint32_t *px = (const uint32_t *)row;
		uint8_t *o = rowbuf;

		for (int x = 0; x < fb_w; x++) {
			uint32_t p = px[x];

			*o++ = (uint8_t)(p >> 16);  /* R */
			*o++ = (uint8_t)(p >> 8);   /* G */
			*o++ = (uint8_t)(p);        /* B */
		}
		semihost_write(fd, rowbuf, (long)fb_w * 3);
		row += pitch;
	}
	semihost_close(fd);
	LOG_INF("present: wrote %s", name);
}
```

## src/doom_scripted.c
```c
/*
 * SPDX-License-Identifier: Apache-2.0
 *
 * PiZZa sdl2-doom -- scripted input source (CONFIG_DOOM_SCRIPTED_INPUT).
 *
 * A synthetic input producer that drives Doom headless through the same
 * sdl2shim event-queue seam a HOGP keyboard client will use later. It
 * runs on its own thread and injects a wall-clock timeline of key
 * press/release events: open the menu, New Game -> episode 1 -> skill ->
 * E1M1, then move and fire in-game. Proves the menu path and in-game
 * input for the qemu sim gate (G2).
 *
 * Events queue in shim_event.c, so the sequence is preserved even under
 * qemu TCG's dilated timing; the spacing is generous so each menu screen
 * and the level load complete between keys (and so the frame capture
 * lands on distinct screens).
 */

#include <zephyr/kernel.h>
#include <zephyr/logging/log.h>

#include "sdl2shim.h"

LOG_MODULE_REGISTER(doom_scripted, CONFIG_SDL2SHIM_LOG_LEVEL);

struct script_step {
	uint32_t at_ms;
	SDL_Scancode scancode;
	bool down;
};

/* Doom 1 shareware menu path: Escape opens the main menu (cursor on New
 * Game); three Returns walk New Game -> Knee-Deep in the Dead -> default
 * skill -> start E1M1 (no Nightmare confirm at the default cursor). Then
 * forward + fire + turn in-game.
 */
static const struct script_step timeline[] = {
	{ 8000,  SDL_SCANCODE_ESCAPE, true }, { 8150,  SDL_SCANCODE_ESCAPE, false },
	{ 12000, SDL_SCANCODE_RETURN, true }, { 12150, SDL_SCANCODE_RETURN, false },
	{ 16000, SDL_SCANCODE_RETURN, true }, { 16150, SDL_SCANCODE_RETURN, false },
	{ 20000, SDL_SCANCODE_RETURN, true }, { 20150, SDL_SCANCODE_RETURN, false },
	/* in-game: forward, fire, turn, forward, fire */
	{ 26000, SDL_SCANCODE_UP,    true },
	{ 30000, SDL_SCANCODE_LCTRL, true }, { 30250, SDL_SCANCODE_LCTRL, false },
	{ 32000, SDL_SCANCODE_UP,    false },
	{ 33000, SDL_SCANCODE_RIGHT, true }, { 35000, SDL_SCANCODE_RIGHT, false },
	{ 36000, SDL_SCANCODE_UP,    true }, { 40000, SDL_SCANCODE_UP,    false },
	{ 41000, SDL_SCANCODE_LCTRL, true }, { 41250, SDL_SCANCODE_LCTRL, false },
};

static K_THREAD_STACK_DEFINE(scripted_stack, 2048);
static struct k_thread scripted_thread;

static void push_key(SDL_Scancode sc, bool down)
{
	SDL_Event ev;

	memset(&ev, 0, sizeof(ev));
	ev.type = down ? SDL_KEYDOWN : SDL_KEYUP;
	ev.key.state = down ? SDL_PRESSED : SDL_RELEASED;
	ev.key.keysym.scancode = sc;
	s2s_event_submit(&ev);
}

static void scripted_run(void *a, void *b, void *c)
{
	ARG_UNUSED(a);
	ARG_UNUSED(b);
	ARG_UNUSED(c);

	int64_t t0 = k_uptime_get();

	for (size_t i = 0; i < ARRAY_SIZE(timeline); i++) {
		int64_t due = t0 + timeline[i].at_ms;
		int64_t now = k_uptime_get();

		if (due > now) {
			k_msleep((int32_t)(due - now));
		}
		push_key(timeline[i].scancode, timeline[i].down);
		LOG_DBG("scripted: t=%u sc=%d %s", timeline[i].at_ms,
			timeline[i].scancode, timeline[i].down ? "down" : "up");
	}
	LOG_INF("scripted: timeline complete");
}

void s2s_scripted_input_start(void)
{
	k_thread_create(&scripted_thread, scripted_stack,
			K_THREAD_STACK_SIZEOF(scripted_stack),
			scripted_run, NULL, NULL, NULL,
			K_PRIO_PREEMPT(7), 0, K_NO_WAIT);
	k_thread_name_set(&scripted_thread, "doom_scripted");
}
```

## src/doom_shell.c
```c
/*
 * SPDX-License-Identifier: Apache-2.0
 *
 * PiZZa Doom port -- `doom` shell command set (USB CDC ACM).
 *
 * Injects key events into the game through the same shim_event.c
 * producer seam the scripted source and the future HOGP keyboard
 * client use (work-order §5b). This is the interactive control path
 * on hardware until the Bluetooth keyboard lands -- you drive Doom
 * over the serial line.
 *
 *   doom key <name>       tap: keydown + keyup (menus, "press any key")
 *   doom down <name>      press and HOLD (movement -- left/right/up/shift)
 *   doom up <name>        release a held key
 *   doom tap <name> [ms]  hold <name> for ms (default 250) then release
 *   doom keys             list key names
 *
 * <name>: left right up down  return|enter  esc  space  shift  ctrl
 *         a..z  and the digits 0..9.
 */

#include <zephyr/kernel.h>
#include <zephyr/shell/shell.h>
#include <stdlib.h>
#include <string.h>
#include <strings.h>   /* strcasecmp (picolibc keeps it here) */

#include "sdl2shim.h"

struct keyname {
	const char *name;
	SDL_Scancode sc;
};

static const struct keyname keymap[] = {
	{ "left", SDL_SCANCODE_LEFT },   { "right", SDL_SCANCODE_RIGHT },
	{ "up", SDL_SCANCODE_UP },       { "down", SDL_SCANCODE_DOWN },
	{ "return", SDL_SCANCODE_RETURN }, { "enter", SDL_SCANCODE_RETURN },
	{ "esc", SDL_SCANCODE_ESCAPE },  { "escape", SDL_SCANCODE_ESCAPE },
	{ "space", SDL_SCANCODE_SPACE }, { "tab", SDL_SCANCODE_TAB },
	{ "backspace", SDL_SCANCODE_BACKSPACE },
	{ "shift", SDL_SCANCODE_LSHIFT }, { "lshift", SDL_SCANCODE_LSHIFT },
	{ "rshift", SDL_SCANCODE_RSHIFT },
	{ "ctrl", SDL_SCANCODE_LCTRL },  { "lctrl", SDL_SCANCODE_LCTRL },
	{ "alt", SDL_SCANCODE_LALT },
	{ "home", SDL_SCANCODE_HOME },   { "end", SDL_SCANCODE_END },
	{ "pageup", SDL_SCANCODE_PAGEUP }, { "pagedown", SDL_SCANCODE_PAGEDOWN },
};

static SDL_Scancode lookup(const char *name)
{
	for (size_t i = 0; i < ARRAY_SIZE(keymap); i++) {
		if (strcasecmp(name, keymap[i].name) == 0) {
			return keymap[i].sc;
		}
	}
	/* single letter a..z */
	if (name[0] && name[1] == '\0') {
		char c = name[0];

		if (c >= 'a' && c <= 'z') {
			return (SDL_Scancode)(SDL_SCANCODE_A + (c - 'a'));
		}
		if (c >= 'A' && c <= 'Z') {
			return (SDL_Scancode)(SDL_SCANCODE_A + (c - 'A'));
		}
		if (c >= '1' && c <= '9') {
			return (SDL_Scancode)(SDL_SCANCODE_1 + (c - '1'));
		}
		if (c == '0') {
			return SDL_SCANCODE_0;
		}
	}
	return SDL_SCANCODE_UNKNOWN;
}

static void submit(SDL_Scancode sc, bool down)
{
	SDL_Event ev;

	memset(&ev, 0, sizeof(ev));
	ev.type = down ? SDL_KEYDOWN : SDL_KEYUP;
	ev.key.state = down ? SDL_PRESSED : SDL_RELEASED;
	ev.key.keysym.scancode = sc;
	s2s_event_submit(&ev);
}

static int arg_key(const struct shell *sh, char *arg, SDL_Scancode *out)
{
	SDL_Scancode sc = lookup(arg);

	if (sc == SDL_SCANCODE_UNKNOWN) {
		shell_error(sh, "unknown key '%s' (try `doom keys`)", arg);
		return -EINVAL;
	}
	*out = sc;
	return 0;
}

static int cmd_key(const struct shell *sh, size_t argc, char **argv)
{
	SDL_Scancode sc;

	if (argc < 2 || arg_key(sh, argv[1], &sc)) {
		return -EINVAL;
	}
	submit(sc, true);
	submit(sc, false);
	shell_print(sh, "tapped %s", argv[1]);
	return 0;
}

static int cmd_down(const struct shell *sh, size_t argc, char **argv)
{
	SDL_Scancode sc;

	if (argc < 2 || arg_key(sh, argv[1], &sc)) {
		return -EINVAL;
	}
	submit(sc, true);
	shell_print(sh, "holding %s (doom up %s to release)", argv[1], argv[1]);
	return 0;
}

static int cmd_up(const struct shell *sh, size_t argc, char **argv)
{
	SDL_Scancode sc;

	if (argc < 2 || arg_key(sh, argv[1], &sc)) {
		return -EINVAL;
	}
	submit(sc, false);
	shell_print(sh, "released %s", argv[1]);
	return 0;
}

static int cmd_tap(const struct shell *sh, size_t argc, char **argv)
{
	SDL_Scancode sc;

	if (argc < 2 || arg_key(sh, argv[1], &sc)) {
		return -EINVAL;
	}

	int ms = (argc >= 3) ? atoi(argv[2]) : 250;

	if (ms <= 0) {
		ms = 250;
	}
	submit(sc, true);
	k_msleep(ms);
	submit(sc, false);
	shell_print(sh, "held %s for %d ms", argv[1], ms);
	return 0;
}

static int cmd_keys(const struct shell *sh, size_t argc, char **argv)
{
	ARG_UNUSED(argc);
	ARG_UNUSED(argv);
	shell_print(sh, "left right up down  return/enter  esc  space  tab  "
			"backspace  shift  ctrl  alt  home end pageup pagedown  "
			"a..z  0..9");
	shell_print(sh, "Doom: arrows move/turn, ctrl = fire, space = "
			"use/open, alt = strafe, esc = menu, enter = confirm");
	return 0;
}

#ifdef CONFIG_SDL2SHIM_AUDIO_HDMI

#include <zephyr/drivers/dma/dma_bcm2835.h>
#include "audio/hdmi_audio.h"

/* HDMI-audio bring-up diagnostics (work order M2): pump/ring
 * counters, live MAI state, recovered clocks, and the raw DMA
 * channel registers -- everything needed to localize a silent-TV
 * fault to feed vs pacing vs MAI vs regen without guessing.
 */
static int cmd_audio(const struct shell *sh, size_t argc, char **argv)
{
	struct s2s_audio_hdmi_stats stats;
	struct hdmi_audio_hw_debug dbg;

	ARG_UNUSED(argc);
	ARG_UNUSED(argv);

	s2s_audio_hdmi_get_stats(&stats);
	shell_print(sh, "state: %s%s%s  dma ch %d",
		    stats.opened ? "open" : "closed",
		    stats.tone_mode ? " [test tone]" : "",
		    stats.opened ? (stats.paused ? " paused" : " playing") : "",
		    stats.dma_chan);
	shell_print(sh, "blocks played %u (%u ms), underruns %u, dma errors %u",
		    stats.blocks_played, stats.blocks_played * 4,
		    stats.underruns, stats.dma_errors);

	hdmi_audio_hw_get_debug(&dbg);
	shell_print(sh, "clocks: hsm %u Hz, pixel %u Hz", dbg.hsm_hz,
		    dbg.pixel_hz);
	shell_print(sh, "MAI: SMP %u/%u  N %u  CTS %u  CTL %08x",
		    dbg.smp_n, dbg.smp_m, dbg.crp_n, dbg.cts, dbg.mai_ctl);

	if (stats.dma_chan >= 0) {
		const struct device *dma =
			DEVICE_DT_GET(DT_NODELABEL(dma));
		struct dma_bcm2835_chan_state cs;

		if (dma_bcm2835_get_chan_state(dma, (uint32_t)stats.dma_chan,
					       &cs) == 0) {
			shell_print(sh, "DMA: CS %08x CONBLK %08x TI %08x",
				    cs.cs, cs.conblk_ad, cs.ti);
			shell_print(sh, "     SRC %08x DST %08x LEN %u DEBUG %08x",
				    cs.source_ad, cs.dest_ad, cs.txfr_len,
				    cs.debug);
		}
	}

	return 0;
}

static int cmd_audio_starve(const struct shell *sh, size_t argc, char **argv)
{
	int blocks = atoi(argv[1]);

	ARG_UNUSED(argc);
	if (blocks <= 0 || blocks > 1000) {
		shell_print(sh, "blocks must be 1..1000");
		return -EINVAL;
	}

	s2s_audio_hdmi_starve((unsigned int)blocks);
	shell_print(sh, "starving feeder for %d blocks (%d ms) -- expect "
		    "~%d underruns, then recovery; check `doom audio`",
		    blocks, blocks * 4, blocks > 7 ? blocks - 7 : 0);
	return 0;
}

#endif /* CONFIG_SDL2SHIM_AUDIO_HDMI */

SHELL_STATIC_SUBCMD_SET_CREATE(sub_doom,
	SHELL_CMD_ARG(key,  NULL, "<name>  -- tap (down+up), e.g. `doom key enter`", cmd_key, 2, 0),
	SHELL_CMD_ARG(down, NULL, "<name>  -- press and hold",  cmd_down, 2, 0),
	SHELL_CMD_ARG(up,   NULL, "<name>  -- release a held key", cmd_up, 2, 0),
	SHELL_CMD_ARG(tap,  NULL, "<name> [ms]  -- hold then release (default 250 ms)", cmd_tap, 2, 1),
	SHELL_CMD(keys,     NULL, "list key names", cmd_keys),
#ifdef CONFIG_SDL2SHIM_AUDIO_HDMI
	SHELL_CMD(audio,    NULL, "HDMI audio path diagnostics", cmd_audio),
	SHELL_CMD_ARG(starve, NULL, "<blocks>  -- starve the audio ring (underrun demo)",
		      cmd_audio_starve, 2, 0),
#endif
	SHELL_SUBCMD_SET_END
);

SHELL_CMD_REGISTER(doom, &sub_doom, "PiZZa Doom input control (inject keys)", NULL);
```

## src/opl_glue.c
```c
/*
 * SPDX-License-Identifier: Apache-2.0
 *
 * PiZZa sdl2-doom -- OPL glue (CONFIG_DOOM_MUSIC_OPL).
 *
 * The handful of SDL/Mix primitives Chocolate Doom's OPL subsystem
 * (opl/opl.c + opl/opl_sdl.c) needs that the shim did not already have:
 * SDL mutex/condvar over Zephyr kernel objects, the saturating
 * SDL_MixAudioFormat that folds the synth output into the post-mix block,
 * and stubs for the two Mix entry points on paths the OPL driver does not
 * take here (Mix is already open -- the SFX mixer owns it).
 */

#include <stdio.h>
#include <stdlib.h>

#include <zephyr/kernel.h>

#include "sdl2shim.h"
#include <SDL2/SDL_mixer.h>

struct SDL_mutex {
	struct k_mutex m;
};

struct SDL_cond {
	struct k_condvar cv;
};

SDL_mutex *SDL_CreateMutex(void)
{
	SDL_mutex *mutex = malloc(sizeof(*mutex));

	if (mutex != NULL) {
		k_mutex_init(&mutex->m);
	}
	return mutex;
}

void SDL_DestroyMutex(SDL_mutex *mutex)
{
	free(mutex);
}

int SDL_LockMutex(SDL_mutex *mutex)
{
	return k_mutex_lock(&mutex->m, K_FOREVER);
}

int SDL_UnlockMutex(SDL_mutex *mutex)
{
	return k_mutex_unlock(&mutex->m);
}

SDL_cond *SDL_CreateCond(void)
{
	SDL_cond *cond = malloc(sizeof(*cond));

	if (cond != NULL) {
		k_condvar_init(&cond->cv);
	}
	return cond;
}

void SDL_DestroyCond(SDL_cond *cond)
{
	free(cond);
}

int SDL_CondSignal(SDL_cond *cond)
{
	return k_condvar_signal(&cond->cv);
}

int SDL_CondWait(SDL_cond *cond, SDL_mutex *mutex)
{
	return k_condvar_wait(&cond->cv, &mutex->m, K_FOREVER);
}

void SDL_MixAudioFormat(Uint8 *dst, const Uint8 *src, SDL_AudioFormat format,
			Uint32 len, int volume)
{
	int16_t *d = (int16_t *)dst;
	const int16_t *s = (const int16_t *)src;
	unsigned int n = len / sizeof(int16_t);

	ARG_UNUSED(format); /* Doom OPL output is always AUDIO_S16SYS */

	for (unsigned int i = 0; i < n; i++) {
		int32_t v = d[i] + (s[i] * volume) / SDL_MIX_MAXVOLUME;

		d[i] = (int16_t)CLAMP(v, -32768, 32767);
	}
}

int Mix_OpenAudioDevice(int frequency, Uint16 format, int channels,
			int chunksize, const char *device, int allowed_changes)
{
	ARG_UNUSED(frequency);
	ARG_UNUSED(format);
	ARG_UNUSED(channels);
	ARG_UNUSED(chunksize);
	ARG_UNUSED(device);
	ARG_UNUSED(allowed_changes);

	/* Never reached: the SFX mixer already opened audio, so opl_sdl.c's
	 * !SDLIsInitialized() branch is not taken. Fail if that ever breaks.
	 */
	return -1;
}

void Mix_HookMusic(Mix_MusicHook mix_func, void *arg)
{
	ARG_UNUSED(mix_func);
	ARG_UNUSED(arg);
}

/* ── Doom helpers the newer Chocolate OPL/MIDI code calls that the older
 *    sdl2-doom fork does not provide ──────────────────────────────────
 */

/* DEH: the fork stubs dehacked; string substitution is a passthrough. */
const char *DEH_String(const char *s)
{
	return s;
}

/* Plain passthrough. i_oplmusic round-trips each song's converted MIDI
 * through a temp file (M_TempFile "doom.mid" -> M_WriteFile -> MIDI_LoadFile);
 * both the fork's M_WriteFile and Chocolate's MIDI_LoadFile funnel through
 * open()/read()/write(), so the RAM temp file lives in the fd layer
 * (doom_assets.c) where both sides see the same buffer.
 */
FILE *M_fopen(const char *filename, const char *mode)
{
	return fopen(filename, mode);
}

int M_remove(const char *path)
{
	return remove(path);
}

void *I_Realloc(void *ptr, size_t size)
{
	return realloc(ptr, size);
}
```

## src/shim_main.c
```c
/*
 * SPDX-License-Identifier: Apache-2.0
 *
 * PiZZa sdl2-doom -- Zephyr entry point.
 *
 * sdl2-doom's i_main.c main() is renamed to SDL_main by a per-file
 * -Dmain=SDL_main (i_main.c does not include <SDL2/SDL.h>, so the
 * header's own main->SDL_main redirect cannot reach it). This main()
 * builds argv and calls it.
 *
 * The IWAD is the rodata-baked WAD the fd layer (doom_assets.c)
 * resolves at "/doom1.wad"; -iwad points Doom straight at it so d_iwad
 * skips its filesystem search.
 */

#include <zephyr/kernel.h>
#include <stdio.h>

#include "sdl2shim.h"

extern int SDL_main(int argc, char *argv[]);

int main(void)
{
	static char *argv[] = {
		"doom",
		"-iwad", "/doom1.wad",
#if defined(CONFIG_DOOM_SIM_TUNING)
		/* Boot straight to E1M1: the title/demo loop renders far too
		 * slowly under qemu TCG to reach interactively.
		 */
		"-warp", "1", "1",
#endif
		NULL,
	};
	int argc = (int)(ARRAY_SIZE(argv) - 1);

	printf("[doom] PiZZa sdl2-doom port, board %s\n", CONFIG_BOARD);

	if (IS_ENABLED(CONFIG_DOOM_SCRIPTED_INPUT)) {
		s2s_scripted_input_start();
	}

	printf("[doom] entering SDL_main (D_DoomMain)\n");

	int rc = SDL_main(argc, argv);

	printf("[doom] game exited: %d\n", rc);
	return rc;
}
```
